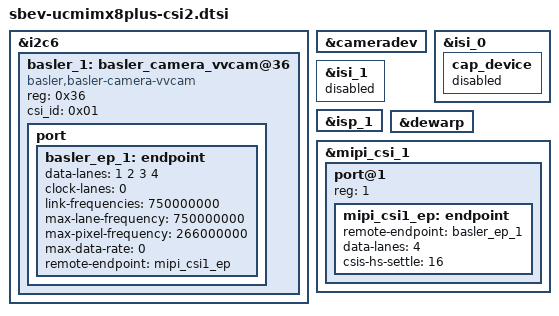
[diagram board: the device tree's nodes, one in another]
#include "sbev-ucmimx8plus-camera-csi2-power.dtsi"

&i2c6 {
	#address-cells = <1>;
	#size-cells = <0>;
	status = "okay";

	basler_1: basler_camera_vvcam@36 {
		compatible = "basler,basler-camera-vvcam", "basler-camera-vvcam";
		reg = <0x36>;
		csi_id = <0x01>;
		status = "okay";

		port {
			basler_ep_1: endpoint {
				data-lanes = <1 2 3 4>;
				clock-lanes = <0>;
				link-frequencies = /bits/ 64 <750000000>;

				max-lane-frequency = /bits/ 64 <750000000>;
				max-pixel-frequency = /bits/ 64 <266000000>;
				max-data-rate = /bits/ 64 <0>;

				remote-endpoint = <&mipi_csi1_ep>;
			};
		};
	};
};

&cameradev {
	status = "okay";
};

&isi_0 {
	cap_device {
		status = "disabled";
	};
};

&isi_1 {
	status = "disabled";
};

&isp_1 {
	status = "okay";
};

&dewarp {
	status = "okay";
};

&mipi_csi_1 {
	#address-cells = <1>;
	#size-cells = <0>;
	status = "okay";

	port@1 {
		reg = <1>;
		mipi_csi1_ep: endpoint {
			remote-endpoint = <&basler_ep_1>;
			data-lanes = <4>;
			csis-hs-settle = <16>;
		};
	};
};
